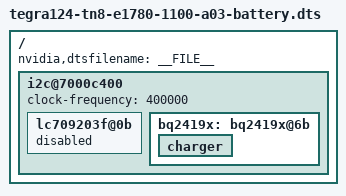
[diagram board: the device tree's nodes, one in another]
#include "tegra124-tn8-e1780-1100-a03.dts"
#include "tegra124-platforms/tegra124-tn8-sysedp-e1780-1100-a02.dtsi"

/ {
	nvidia,dtsfilename = __FILE__;

	i2c@7000c400 {
		status = "okay";
		clock-frequency = <400000>;

		lc709203f@0b {
			status = "disabled";
		};

		bq2419x: bq2419x@6b {
			charger {
				status = "okay";
			};
		};
	};
};

